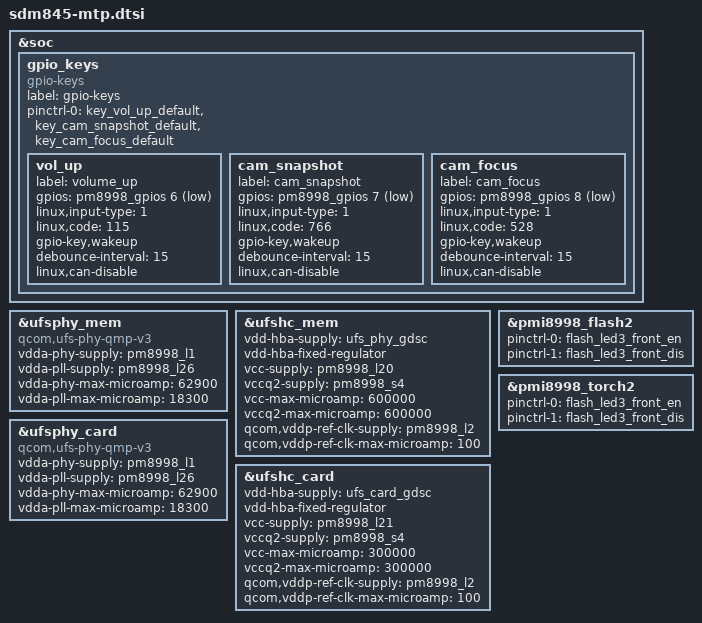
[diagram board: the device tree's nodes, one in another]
/* Copyright (c) 2016-2017, The Linux Foundation. All rights reserved.
 *
 * This program is free software; you can redistribute it and/or modify
 * it under the terms of the GNU General Public License version 2 and
 * only version 2 as published by the Free Software Foundation.
 *
 * This program is distributed in the hope that it will be useful,
 * but WITHOUT ANY WARRANTY; without even the implied warranty of
 * MERCHANTABILITY or FITNESS FOR A PARTICULAR PURPOSE.  See the
 * GNU General Public License for more details.
 */

#include <dt-bindings/gpio/gpio.h>

&soc {
	gpio_keys {
		compatible = "gpio-keys";
		label = "gpio-keys";

		pinctrl-names = "default";
		pinctrl-0 = <&key_vol_up_default
			     &key_cam_snapshot_default
			     &key_cam_focus_default>;

		vol_up {
			label = "volume_up";
			gpios = <&pm8998_gpios 6 GPIO_ACTIVE_LOW>;
			linux,input-type = <1>;
			linux,code = <115>;
			gpio-key,wakeup;
			debounce-interval = <15>;
			linux,can-disable;
		};

		cam_snapshot {
			label = "cam_snapshot";
			gpios = <&pm8998_gpios 7 GPIO_ACTIVE_LOW>;
			linux,input-type = <1>;
			linux,code = <766>;
			gpio-key,wakeup;
			debounce-interval = <15>;
			linux,can-disable;
		};

		cam_focus {
			label = "cam_focus";
			gpios = <&pm8998_gpios 8 GPIO_ACTIVE_LOW>;
			linux,input-type = <1>;
			linux,code = <528>;
			gpio-key,wakeup;
			debounce-interval = <15>;
			linux,can-disable;
		};
	};
};

&ufsphy_mem {
	compatible = "qcom,ufs-phy-qmp-v3";

	vdda-phy-supply = <&pm8998_l1>; /* 0.88v */
	vdda-pll-supply = <&pm8998_l26>; /* 1.2v */
	vdda-phy-max-microamp = <62900>;
	vdda-pll-max-microamp = <18300>;

	status = "ok";
};

&ufshc_mem {
	vdd-hba-supply = <&ufs_phy_gdsc>;
	vdd-hba-fixed-regulator;
	vcc-supply = <&pm8998_l20>;
	vccq2-supply = <&pm8998_s4>;
	vcc-max-microamp = <600000>;
	vccq2-max-microamp = <600000>;

	qcom,vddp-ref-clk-supply = <&pm8998_l2>;
	qcom,vddp-ref-clk-max-microamp = <100>;

	status = "ok";
};

&ufsphy_card {
	compatible = "qcom,ufs-phy-qmp-v3";

	vdda-phy-supply = <&pm8998_l1>; /* 0.88v */
	vdda-pll-supply = <&pm8998_l26>; /* 1.2v */
	vdda-phy-max-microamp = <62900>;
	vdda-pll-max-microamp = <18300>;

	status = "ok";
};

&ufshc_card {
	vdd-hba-supply = <&ufs_card_gdsc>;
	vdd-hba-fixed-regulator;
	vcc-supply = <&pm8998_l21>;
	vccq2-supply = <&pm8998_s4>;
	vcc-max-microamp = <300000>;
	vccq2-max-microamp = <300000>;

	qcom,vddp-ref-clk-supply = <&pm8998_l2>;
	qcom,vddp-ref-clk-max-microamp = <100>;

	status = "ok";
};

&pmi8998_flash2 {
	pinctrl-names = "led_enable", "led_disable";
	pinctrl-0 = <&flash_led3_front_en>;
	pinctrl-1 = <&flash_led3_front_dis>;
};

&pmi8998_torch2 {
	pinctrl-names = "led_enable", "led_disable";
	pinctrl-0 = <&flash_led3_front_en>;
	pinctrl-1 = <&flash_led3_front_dis>;
};
